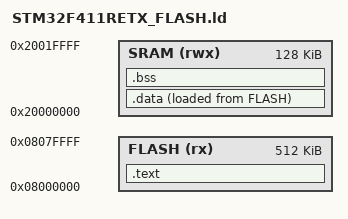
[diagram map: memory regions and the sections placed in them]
/* Entry Point */
ENTRY(Reset_Handler)

/* Memories definition */
MEMORY
{
  FLASH (rx)  : ORIGIN = 0x08000000, LENGTH = 512K
  SRAM  (rwx) : ORIGIN = 0x20000000, LENGTH = 128K
}

/* Sections */
SECTIONS
{
  /* The program code and other data into "FLASH" Rom type memory */
  .text :
  {
    *(.isr_vector)     /* The startup code into "FLASH" Rom type memory */
    *(.text)           /* .text sections (code) */
    *(.text*)          /* .text* sections (code) */
    *(.glue_7)         /* glue arm to thumb code */
    *(.glue_7t)        /* glue thumb to arm code */
    *(.eh_frame)
    *(.init)
    *(.fini)
    *(.rodata)         /* .rodata sections (constants, strings, etc.) */
    *(.rodata*)        /* .rodata* sections (constants, strings, etc.) */

    . = ALIGN(4);
    _etext = .;        /* define a global symbols at end of code */
  } >FLASH

  _data_load_address = LOADADDR(.data);
  /* Initialized data sections into "RAM" Ram type memory */
  .data :
  {
    _sdata = .;        /* create a global symbol at data start */
    *(.data)           /* .data sections */
    *(.data*)          /* .data* sections */

    . = ALIGN(4);
    _edata = .;        /* define a global symbol at data end */

  } >SRAM AT> FLASH

  /* Uninitialized data section into "RAM" Ram type memory */
  .bss :
  {
    /* This is used by the startup in order to initialize the .bss section */
    _sbss = .;         /* define a global symbol at bss start */
    __bss_start__ = _sbss;
    *(.bss)
    *(.bss*)
    *(COMMON)

    . = ALIGN(4);
    _ebss = .;         /* define a global symbol at bss end */
    __bss_end__ = _ebss;
    . = ALIGN(4);
    _end = .;
    end = _end;
  } >SRAM
}
